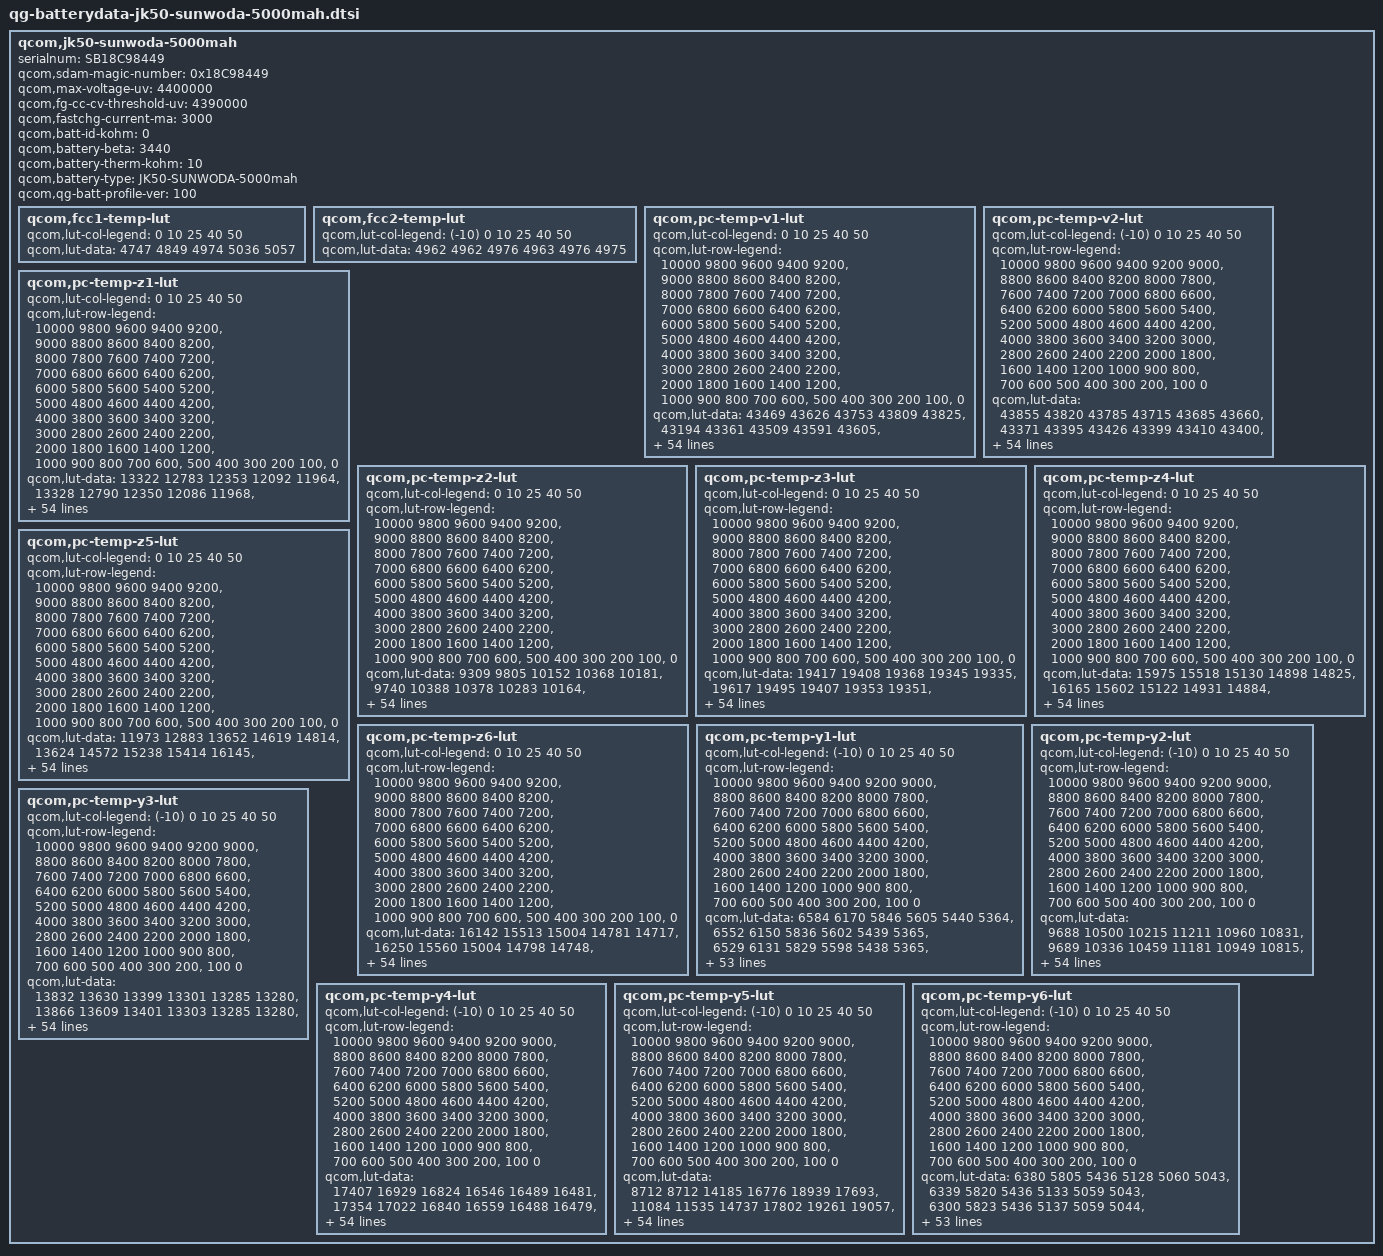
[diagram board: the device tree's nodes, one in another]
qcom,jk50-sunwoda-5000mah {
    /* 4875124_Lenovo_Ibiza_sunwoda_5000mAH_PM7250B_averaged_MasterSlave_Dec1th2020 */
    serialnum = "SB18C98449";
    qcom,sdam-magic-number = <0x18C98449>;
    qcom,max-voltage-uv = <4400000>;
    qcom,fg-cc-cv-threshold-uv = <4390000>;
    qcom,fastchg-current-ma = <3000>;
    qcom,batt-id-kohm = <0>;
    qcom,battery-beta = <3440>;
    qcom,battery-therm-kohm = <10>;
    qcom,battery-type = "JK50-SUNWODA-5000mah";
    qcom,qg-batt-profile-ver = <100>;

	qcom,fcc1-temp-lut {
		qcom,lut-col-legend = <0 10 25 40 50>;
		qcom,lut-data = <4747 4849 4974 5036 5057>;
	};

	qcom,fcc2-temp-lut {
		qcom,lut-col-legend = <(-10) 0 10 25 40 50>;
		qcom,lut-data = <4962 4962 4976 4963 4976 4975>;
	};

	qcom,pc-temp-v1-lut {
		qcom,lut-col-legend = <0 10 25 40 50>;
		qcom,lut-row-legend = <10000 9800 9600 9400 9200>,
			<9000 8800 8600 8400 8200>,
			<8000 7800 7600 7400 7200>,
			<7000 6800 6600 6400 6200>,
			<6000 5800 5600 5400 5200>,
			<5000 4800 4600 4400 4200>,
			<4000 3800 3600 3400 3200>,
			<3000 2800 2600 2400 2200>,
			<2000 1800 1600 1400 1200>,
			<1000 900 800 700 600>,
			<500 400 300 200 100>,
			<0>;
		qcom,lut-data = <43469 43626 43753 43809 43825>,
			<43194 43361 43509 43591 43605>,
			<42948 43112 43267 43360 43385>,
			<42714 42875 43026 43127 43162>,
			<42489 42643 42786 42894 42930>,
			<42273 42416 42550 42658 42692>,
			<42065 42196 42319 42425 42459>,
			<41864 41983 42092 42192 42227>,
			<41670 41778 41871 41963 41999>,
			<41485 41578 41655 41738 41772>,
			<41301 41391 41447 41516 41547>,
			<41101 41202 41256 41299 41327>,
			<40886 40997 41064 41085 41108>,
			<40655 40778 40850 40878 40897>,
			<40385 40547 40618 40674 40691>,
			<40094 40277 40392 40475 40492>,
			<39888 40016 40166 40276 40300>,
			<39766 39853 39963 40078 40115>,
			<39666 39751 39821 39902 39939>,
			<39560 39649 39716 39764 39788>,
			<39453 39522 39580 39618 39633>,
			<39344 39377 39334 39388 39412>,
			<39227 39204 39067 39089 39117>,
			<39106 38960 38892 38889 38906>,
			<38974 38745 38759 38775 38793>,
			<38820 38637 38655 38682 38702>,
			<38676 38563 38576 38588 38595>,
			<38575 38505 38510 38500 38484>,
			<38494 38457 38444 38414 38387>,
			<38435 38416 38380 38328 38306>,
			<38397 38377 38321 38251 38234>,
			<38368 38341 38265 38185 38168>,
			<38338 38305 38214 38128 38109>,
			<38311 38271 38168 38075 38050>,
			<38284 38239 38129 38028 37993>,
			<38256 38205 38090 37983 37936>,
			<38226 38173 38052 37935 37881>,
			<38187 38133 38012 37885 37827>,
			<38124 38066 37950 37818 37756>,
			<38041 37969 37856 37723 37655>,
			<37941 37862 37750 37616 37540>,
			<37811 37741 37635 37505 37427>,
			<37674 37602 37503 37380 37301>,
			<37532 37432 37335 37217 37136>,
			<37405 37291 37191 37083 37011>,
			<37300 37192 37100 36999 36934>,
			<37263 37169 37070 36969 36909>,
			<37232 37161 37050 36948 36890>,
			<37201 37147 37027 36928 36866>,
			<37145 37092 36980 36871 36800>,
			<36941 36873 36747 36614 36522>,
			<36499 36428 36311 36176 36084>,
			<35925 35856 35736 35602 35511>,
			<35155 35077 34956 34825 34730>,
			<33936 33856 33739 33613 33519>,
			<30000 30000 30000 30000 30000>;
	};

	qcom,pc-temp-v2-lut {
		qcom,lut-col-legend = <(-10) 0 10 25 40 50>;
		qcom,lut-row-legend = <10000 9800 9600 9400 9200 9000>,
			<8800 8600 8400 8200 8000 7800>,
			<7600 7400 7200 7000 6800 6600>,
			<6400 6200 6000 5800 5600 5400>,
			<5200 5000 4800 4600 4400 4200>,
			<4000 3800 3600 3400 3200 3000>,
			<2800 2600 2400 2200 2000 1800>,
			<1600 1400 1200 1000 900 800>,
			<700 600 500 400 300 200>,
			<100 0>;
		qcom,lut-data = <43855 43820 43785 43715 43685 43660>,
			<43371 43395 43426 43399 43410 43400>,
			<42943 43013 43096 43106 43146 43147>,
			<42579 42683 42800 42839 42895 42903>,
			<42268 42399 42533 42598 42656 42667>,
			<41985 42130 42283 42364 42421 42433>,
			<41666 41820 42050 42129 42188 42199>,
			<41390 41529 41826 41897 41959 41967>,
			<41327 41385 41572 41672 41732 41739>,
			<41322 41291 41267 41451 41509 41515>,
			<41315 41207 41044 41240 41288 41293>,
			<41060 41077 40963 41052 41072 41075>,
			<40528 40857 40904 40871 40859 40861>,
			<40142 40574 40746 40655 40648 40655>,
			<39815 40116 40296 40385 40435 40453>,
			<39547 39722 39902 40133 40234 40259>,
			<39374 39543 39761 39946 40051 40075>,
			<39229 39415 39661 39784 39880 39898>,
			<39044 39258 39513 39638 39718 39730>,
			<38781 39065 39290 39514 39572 39578>,
			<38555 38858 39059 39376 39411 39411>,
			<38434 38623 38859 39158 39184 39186>,
			<38345 38382 38671 38886 38925 38934>,
			<38271 38244 38500 38686 38732 38743>,
			<38209 38171 38334 38543 38589 38598>,
			<38155 38117 38197 38423 38468 38474>,
			<38103 38069 38099 38314 38359 38362>,
			<38055 38028 38018 38217 38262 38262>,
			<38007 37990 37964 38128 38173 38172>,
			<37960 37953 37927 38045 38091 38091>,
			<37912 37917 37894 37970 38018 38018>,
			<37864 37882 37863 37902 37955 37953>,
			<37815 37845 37833 37841 37898 37893>,
			<37763 37807 37800 37791 37835 37828>,
			<37712 37768 37764 37756 37764 37756>,
			<37657 37727 37725 37720 37688 37677>,
			<37596 37683 37682 37672 37607 37579>,
			<37531 37637 37635 37613 37522 37468>,
			<37459 37579 37575 37545 37442 37374>,
			<37376 37505 37497 37468 37368 37302>,
			<37291 37417 37405 37380 37290 37229>,
			<37214 37315 37295 37277 37197 37135>,
			<37141 37195 37166 37156 37088 37024>,
			<37070 37056 37038 37026 36960 36899>,
			<36997 36926 36917 36909 36851 36798>,
			<36915 36843 36812 36839 36798 36749>,
			<36867 36816 36779 36820 36787 36738>,
			<36812 36786 36747 36799 36770 36720>,
			<36742 36750 36697 36769 36740 36691>,
			<36635 36676 36616 36697 36659 36593>,
			<36418 36485 36418 36498 36388 36285>,
			<36023 36062 36003 36052 35909 35794>,
			<35447 35449 35397 35450 35288 35159>,
			<34604 34590 34552 34643 34456 34298>,
			<33231 33266 33257 33424 33243 33051>,
			<29354 28911 28617 28464 28599 28631>;
	};

	qcom,pc-temp-z1-lut {
		qcom,lut-col-legend = <0 10 25 40 50>;
		qcom,lut-row-legend = <10000 9800 9600 9400 9200>,
			<9000 8800 8600 8400 8200>,
			<8000 7800 7600 7400 7200>,
			<7000 6800 6600 6400 6200>,
			<6000 5800 5600 5400 5200>,
			<5000 4800 4600 4400 4200>,
			<4000 3800 3600 3400 3200>,
			<3000 2800 2600 2400 2200>,
			<2000 1800 1600 1400 1200>,
			<1000 900 800 700 600>,
			<500 400 300 200 100>,
			<0>;
		qcom,lut-data = <13322 12783 12353 12092 11964>,
			<13328 12790 12350 12086 11968>,
			<13352 12780 12345 12077 11961>,
			<13358 12758 12341 12069 11952>,
			<13343 12743 12334 12059 11946>,
			<13329 12730 12325 12049 11940>,
			<13324 12723 12314 12042 11936>,
			<13319 12727 12304 12035 11933>,
			<13313 12737 12303 12031 11932>,
			<13293 12740 12303 12029 11932>,
			<13270 12731 12303 12028 11932>,
			<13259 12716 12299 12029 11934>,
			<13242 12699 12294 12033 11938>,
			<13219 12677 12286 12034 11940>,
			<13186 12664 12274 12025 11937>,
			<13150 12653 12268 12016 11933>,
			<13133 12643 12267 12015 11932>,
			<13131 12642 12266 12016 11933>,
			<13130 12656 12270 12017 11934>,
			<13125 12666 12283 12020 11935>,
			<13120 12665 12290 12024 11935>,
			<13121 12663 12289 12027 11936>,
			<13126 12663 12288 12028 11937>,
			<13133 12671 12291 12030 11938>,
			<13137 12681 12301 12032 11941>,
			<13135 12687 12307 12034 11944>,
			<13131 12693 12307 12037 11946>,
			<13133 12696 12308 12039 11948>,
			<13138 12696 12309 12042 11951>,
			<13141 12697 12314 12046 11954>,
			<13143 12703 12318 12050 11958>,
			<13144 12715 12320 12053 11961>,
			<13148 12723 12325 12056 11964>,
			<13159 12723 12330 12060 11967>,
			<13172 12721 12338 12066 11971>,
			<13191 12724 12344 12072 11976>,
			<13218 12738 12349 12076 11979>,
			<13228 12750 12355 12080 11982>,
			<13215 12755 12360 12085 11986>,
			<13198 12760 12365 12089 11990>,
			<13197 12765 12369 12094 11994>,
			<13208 12780 12370 12100 11999>,
			<13219 12789 12372 12106 12005>,
			<13230 12790 12379 12109 12008>,
			<13249 12796 12399 12118 12013>,
			<13263 12810 12396 12124 12016>,
			<13267 12815 12402 12121 12014>,
			<13263 12817 12396 12123 12015>,
			<13263 12812 12396 12127 12018>,
			<13296 12815 12408 12133 12025>,
			<13294 12830 12409 12140 12030>,
			<13327 12836 12433 12150 12038>,
			<13305 12864 12427 12165 12049>,
			<13343 12895 12461 12177 12067>,
			<13343 12895 12461 12177 12067>,
			<13343 12895 12461 12177 12067>;
	};

	qcom,pc-temp-z2-lut {
		qcom,lut-col-legend = <0 10 25 40 50>;
		qcom,lut-row-legend = <10000 9800 9600 9400 9200>,
			<9000 8800 8600 8400 8200>,
			<8000 7800 7600 7400 7200>,
			<7000 6800 6600 6400 6200>,
			<6000 5800 5600 5400 5200>,
			<5000 4800 4600 4400 4200>,
			<4000 3800 3600 3400 3200>,
			<3000 2800 2600 2400 2200>,
			<2000 1800 1600 1400 1200>,
			<1000 900 800 700 600>,
			<500 400 300 200 100>,
			<0>;
		qcom,lut-data = <9309 9805 10152 10368 10181>,
			<9740 10388 10378 10283 10164>,
			<10173 10438 10515 10372 10169>,
			<10314 10457 10530 10414 10179>,
			<10315 10460 10532 10374 10220>,
			<10310 10443 10527 10317 10284>,
			<10305 10420 10490 10288 10288>,
			<10302 10404 10446 10252 10219>,
			<10297 10389 10428 10237 10155>,
			<10292 10377 10417 10242 10108>,
			<10284 10367 10407 10250 10064>,
			<10270 10358 10394 10265 10059>,
			<10239 10354 10384 10288 10076>,
			<10216 10350 10392 10295 10087>,
			<10218 10349 10421 10240 10084>,
			<10225 10363 10435 10174 10079>,
			<10225 10385 10422 10159 10084>,
			<10213 10394 10404 10154 10104>,
			<10200 10398 10400 10159 10125>,
			<10201 10404 10405 10171 10141>,
			<10214 10430 10421 10193 10161>,
			<10232 10475 10556 10322 10221>,
			<10253 10504 10712 10602 10353>,
			<10278 10522 10698 10685 10408>,
			<10306 10536 10573 10445 10325>,
			<10341 10548 10505 10215 10231>,
			<10372 10560 10507 10233 10359>,
			<10387 10565 10514 10313 10771>,
			<10397 10560 10529 10387 10933>,
			<10401 10553 10565 10488 10728>,
			<10399 10552 10591 10559 10456>,
			<10396 10555 10601 10538 10287>,
			<10396 10558 10609 10475 10146>,
			<10406 10561 10610 10409 10107>,
			<10419 10566 10607 10324 10115>,
			<10431 10573 10607 10271 10129>,
			<10444 10583 10613 10280 10161>,
			<10457 10596 10622 10305 10216>,
			<10469 10612 10639 10342 10261>,
			<10481 10629 10670 10416 10302>,
			<10493 10637 10689 10464 10327>,
			<10507 10638 10677 10456 10329>,
			<10485 10638 10662 10445 10327>,
			<10309 10640 10657 10469 10374>,
			<10552 10746 10679 10467 10374>,
			<10569 10758 10680 10438 10324>,
			<10942 10757 10669 10422 10328>,
			<11114 11385 10612 10419 10335>,
			<11107 14000 10613 10443 10353>,
			<11006 12103 10692 10515 10414>,
			<10724 14471 10668 10491 10374>,
			<10236 11170 10637 10354 10191>,
			<10094 10757 10551 10290 10139>,
			<9835 10903 10470 10257 10091>,
			<9835 10903 10470 10257 10091>,
			<9835 10903 10470 10257 10091>;
	};

	qcom,pc-temp-z3-lut {
		qcom,lut-col-legend = <0 10 25 40 50>;
		qcom,lut-row-legend = <10000 9800 9600 9400 9200>,
			<9000 8800 8600 8400 8200>,
			<8000 7800 7600 7400 7200>,
			<7000 6800 6600 6400 6200>,
			<6000 5800 5600 5400 5200>,
			<5000 4800 4600 4400 4200>,
			<4000 3800 3600 3400 3200>,
			<3000 2800 2600 2400 2200>,
			<2000 1800 1600 1400 1200>,
			<1000 900 800 700 600>,
			<500 400 300 200 100>,
			<0>;
		qcom,lut-data = <19417 19408 19368 19345 19335>,
			<19617 19495 19407 19353 19351>,
			<19668 19529 19434 19377 19363>,
			<19680 19550 19445 19392 19372>,
			<19682 19556 19453 19396 19381>,
			<19684 19556 19455 19399 19389>,
			<19681 19555 19454 19400 19392>,
			<19673 19553 19453 19401 19393>,
			<19666 19549 19451 19402 19394>,
			<19663 19546 19449 19401 19393>,
			<19660 19542 19447 19400 19391>,
			<19655 19538 19443 19400 19389>,
			<19647 19529 19439 19400 19386>,
			<19641 19516 19435 19399 19383>,
			<19646 19509 19431 19392 19380>,
			<19657 19509 19428 19384 19377>,
			<19660 19509 19426 19381 19374>,
			<19642 19506 19423 19378 19371>,
			<19616 19493 19417 19375 19368>,
			<19602 19484 19408 19369 19362>,
			<19592 19483 19404 19364 19356>,
			<19588 19483 19414 19369 19358>,
			<19588 19484 19426 19382 19365>,
			<19588 19488 19425 19386 19368>,
			<19589 19493 19415 19369 19353>,
			<19595 19493 19408 19353 19336>,
			<19602 19491 19406 19355 19350>,
			<19602 19489 19406 19363 19397>,
			<19599 19487 19407 19373 19416>,
			<19595 19485 19412 19389 19411>,
			<19589 19483 19417 19401 19403>,
			<19582 19482 19420 19400 19395>,
			<19576 19481 19422 19396 19387>,
			<19570 19479 19422 19391 19379>,
			<19564 19478 19419 19383 19372>,
			<19558 19475 19416 19375 19366>,
			<19553 19471 19411 19370 19359>,
			<19548 19466 19406 19365 19352>,
			<19544 19464 19403 19364 19349>,
			<19540 19462 19402 19362 19349>,
			<19535 19459 19400 19362 19349>,
			<19530 19455 19396 19360 19351>,
			<19505 19450 19392 19359 19354>,
			<19398 19447 19390 19360 19359>,
			<19271 19425 19383 19357 19356>,
			<19260 19419 19371 19346 19347>,
			<19259 19401 19369 19344 19340>,
			<19259 19327 19365 19339 19330>,
			<19259 19259 19362 19334 19326>,
			<19259 19259 19357 19328 19322>,
			<19259 19258 19357 19341 19335>,
			<19261 19260 19361 19355 19351>,
			<19262 19261 19364 19358 19350>,
			<19264 19260 19354 19349 19347>,
			<19264 19260 19354 19349 19347>,
			<19264 19260 19354 19349 19347>;
	};

	qcom,pc-temp-z4-lut {
		qcom,lut-col-legend = <0 10 25 40 50>;
		qcom,lut-row-legend = <10000 9800 9600 9400 9200>,
			<9000 8800 8600 8400 8200>,
			<8000 7800 7600 7400 7200>,
			<7000 6800 6600 6400 6200>,
			<6000 5800 5600 5400 5200>,
			<5000 4800 4600 4400 4200>,
			<4000 3800 3600 3400 3200>,
			<3000 2800 2600 2400 2200>,
			<2000 1800 1600 1400 1200>,
			<1000 900 800 700 600>,
			<500 400 300 200 100>,
			<0>;
		qcom,lut-data = <15975 15518 15130 14898 14825>,
			<16165 15602 15122 14931 14884>,
			<15998 15513 15104 14913 14871>,
			<15823 15323 15064 14890 14853>,
			<15649 15185 14983 14862 14834>,
			<15488 15091 14919 14832 14814>,
			<15362 15013 14876 14808 14794>,
			<15257 14951 14841 14787 14776>,
			<15172 14899 14813 14768 14760>,
			<15107 14860 14790 14750 14746>,
			<15052 14831 14770 14735 14733>,
			<14995 14807 14752 14724 14723>,
			<14933 14783 14737 14715 14715>,
			<14896 14758 14727 14710 14709>,
			<14892 14748 14720 14706 14705>,
			<14892 14754 14718 14704 14701>,
			<14888 14763 14721 14703 14698>,
			<14859 14759 14724 14702 14696>,
			<14819 14729 14716 14700 14693>,
			<14792 14707 14691 14688 14684>,
			<14768 14706 14680 14676 14676>,
			<14752 14707 14724 14703 14698>,
			<14743 14715 14787 14778 14778>,
			<14737 14782 14815 14812 14816>,
			<14737 14844 14834 14820 14817>,
			<14760 14845 14840 14823 14817>,
			<14786 14835 14829 14814 14797>,
			<14795 14824 14809 14788 14736>,
			<14800 14809 14793 14762 14705>,
			<14802 14793 14776 14736 14701>,
			<14795 14779 14762 14715 14699>,
			<14783 14766 14751 14708 14695>,
			<14772 14755 14742 14703 14692>,
			<14762 14745 14736 14701 14689>,
			<14752 14737 14733 14700 14687>,
			<14742 14730 14730 14700 14686>,
			<14732 14722 14725 14698 14686>,
			<14725 14717 14722 14696 14686>,
			<14719 14718 14722 14697 14688>,
			<14715 14720 14723 14705 14700>,
			<14712 14720 14724 14711 14710>,
			<14710 14714 14717 14704 14703>,
			<14725 14706 14707 14695 14692>,
			<14819 14700 14701 14694 14694>,
			<14884 14676 14681 14681 14685>,
			<14885 14664 14665 14663 14661>,
			<14881 14675 14658 14658 14658>,
			<14876 14743 14651 14648 14651>,
			<14869 14804 14643 14635 14633>,
			<14859 14799 14639 14630 14626>,
			<14858 14802 14653 14650 14660>,
			<14874 14816 14660 14654 14665>,
			<14883 14819 14659 14657 14673>,
			<14894 14824 14671 14666 14679>,
			<14894 14824 14671 14666 14679>,
			<14894 14824 14671 14666 14679>;
	};

	qcom,pc-temp-z5-lut {
		qcom,lut-col-legend = <0 10 25 40 50>;
		qcom,lut-row-legend = <10000 9800 9600 9400 9200>,
			<9000 8800 8600 8400 8200>,
			<8000 7800 7600 7400 7200>,
			<7000 6800 6600 6400 6200>,
			<6000 5800 5600 5400 5200>,
			<5000 4800 4600 4400 4200>,
			<4000 3800 3600 3400 3200>,
			<3000 2800 2600 2400 2200>,
			<2000 1800 1600 1400 1200>,
			<1000 900 800 700 600>,
			<500 400 300 200 100>,
			<0>;
		qcom,lut-data = <11973 12883 13652 14619 14814>,
			<13624 14572 15238 15414 16145>,
			<14390 15684 16618 17257 17212>,
			<14942 16578 17757 18592 18269>,
			<15401 17447 18732 19125 19497>,
			<15807 18258 19614 19549 20759>,
			<16226 19079 20374 20123 21727>,
			<16648 20035 21135 20900 22485>,
			<17159 21178 22080 21739 23188>,
			<17854 22466 23196 22632 23904>,
			<18631 24144 24287 23689 24646>,
			<19337 25633 25374 25323 25486>,
			<19978 26284 26421 27644 26495>,
			<20796 26624 27711 28644 27483>,
			<22643 27126 29646 27821 28446>,
			<25138 28911 30473 26811 29382>,
			<26021 30943 29277 26545 30191>,
			<25089 31303 27817 26159 31017>,
			<23908 31131 28188 26387 31718>,
			<23892 31030 30703 27769 32219>,
			<25149 34887 34466 29941 32756>,
			<27106 43230 44658 34176 33840>,
			<30572 48723 55019 40793 35621>,
			<35766 52415 52775 42253 36121>,
			<41646 54546 39376 31179 27854>,
			<50639 52727 30433 20494 18443>,
			<57834 47079 27757 19844 20763>,
			<58125 42926 26249 19945 30366>,
			<56106 40463 26392 20675 34887>,
			<53519 38875 27886 25539 35032>,
			<50020 38770 29899 30894 34828>,
			<46103 39135 33016 33657 34562>,
			<43673 39704 36626 35726 33911>,
			<41994 41396 39230 36159 33775>,
			<40861 43692 41496 35541 34316>,
			<40292 44627 42436 35001 34782>,
			<39877 45038 41879 34942 34167>,
			<39870 45345 40885 34872 32548>,
			<41202 45682 40179 34711 31417>,
			<42764 46051 39660 34112 30538>,
			<42810 45857 38857 33328 29940>,
			<41486 42490 35589 31155 29729>,
			<37802 40708 33049 28930 29780>,
			<26245 40731 33618 30892 33606>,
			<13058 40549 34936 31403 34029>,
			<11841 40760 32111 27329 29569>,
			<11763 35960 31753 26024 25067>,
			<11709 24395 30263 25468 21822>,
			<11688 11801 31095 27066 24993>,
			<11704 11837 29953 26592 27073>,
			<11753 11891 26279 27520 26082>,
			<11758 11867 23435 25863 23265>,
			<11637 11752 23368 24239 20025>,
			<11543 11618 19023 18876 16846>,
			<11543 11618 19023 18876 16846>,
			<11543 11618 19023 18876 16846>;
	};

	qcom,pc-temp-z6-lut {
		qcom,lut-col-legend = <0 10 25 40 50>;
		qcom,lut-row-legend = <10000 9800 9600 9400 9200>,
			<9000 8800 8600 8400 8200>,
			<8000 7800 7600 7400 7200>,
			<7000 6800 6600 6400 6200>,
			<6000 5800 5600 5400 5200>,
			<5000 4800 4600 4400 4200>,
			<4000 3800 3600 3400 3200>,
			<3000 2800 2600 2400 2200>,
			<2000 1800 1600 1400 1200>,
			<1000 900 800 700 600>,
			<500 400 300 200 100>,
			<0>;
		qcom,lut-data = <16142 15513 15004 14781 14717>,
			<16250 15560 15004 14798 14748>,
			<16153 15511 15004 14797 14747>,
			<16047 15407 14993 14795 14745>,
			<15931 15328 14954 14785 14741>,
			<15820 15267 14920 14769 14736>,
			<15732 15215 14896 14758 14730>,
			<15655 15172 14875 14749 14722>,
			<15592 15134 14859 14740 14715>,
			<15544 15104 14844 14732 14708>,
			<15502 15080 14832 14725 14702>,
			<15454 15058 14820 14720 14696>,
			<15397 15031 14809 14717 14692>,
			<15355 14998 14800 14713 14688>,
			<15338 14980 14790 14705 14684>,
			<15327 14976 14786 14698 14680>,
			<15312 14974 14785 14695 14676>,
			<15282 14967 14785 14694 14674>,
			<15249 14950 14779 14691 14670>,
			<15226 14939 14766 14683 14663>,
			<15207 14939 14760 14675 14657>,
			<15196 14942 14786 14690 14667>,
			<15194 14950 14821 14731 14705>,
			<15192 14982 14830 14746 14723>,
			<15194 15011 14835 14742 14717>,
			<15208 15012 14836 14736 14709>,
			<15225 15009 14831 14731 14707>,
			<15230 15005 14824 14726 14706>,
			<15233 15000 14819 14722 14705>,
			<15233 14993 14816 14720 14701>,
			<15230 14988 14813 14718 14696>,
			<15222 14983 14811 14715 14691>,
			<15217 14979 14810 14712 14686>,
			<15212 14976 14808 14708 14681>,
			<15208 14973 14806 14704 14677>,
			<15204 14971 14805 14701 14674>,
			<15200 14969 14802 14698 14670>,
			<15198 14967 14800 14695 14666>,
			<15200 14970 14800 14695 14666>,
			<15204 14976 14803 14699 14671>,
			<15208 14978 14805 14701 14675>,
			<15213 14977 14801 14699 14674>,
			<15216 14977 14798 14696 14672>,
			<15217 14980 14798 14697 14676>,
			<15205 14970 14791 14691 14670>,
			<15200 14966 14781 14678 14656>,
			<15199 14963 14777 14674 14651>,
			<15198 14956 14772 14668 14643>,
			<15197 14951 14768 14660 14633>,
			<15198 14953 14767 14656 14629>,
			<15207 14960 14778 14674 14652>,
			<15223 14974 14787 14685 14665>,
			<15239 14987 14793 14692 14671>,
			<15268 15004 14802 14696 14676>,
			<15268 15004 14802 14696 14676>,
			<15268 15004 14802 14696 14676>;
	};

	qcom,pc-temp-y1-lut {
		qcom,lut-col-legend = <(-10) 0 10 25 40 50>;
		qcom,lut-row-legend = <10000 9800 9600 9400 9200 9000>,
			<8800 8600 8400 8200 8000 7800>,
			<7600 7400 7200 7000 6800 6600>,
			<6400 6200 6000 5800 5600 5400>,
			<5200 5000 4800 4600 4400 4200>,
			<4000 3800 3600 3400 3200 3000>,
			<2800 2600 2400 2200 2000 1800>,
			<1600 1400 1200 1000 900 800>,
			<700 600 500 400 300 200>,
			<100 0>;
		qcom,lut-data = <6584 6170 5846 5605 5440 5364>,
			<6552 6150 5836 5602 5439 5365>,
			<6529 6131 5829 5598 5438 5365>,
			<6515 6116 5824 5594 5436 5365>,
			<6508 6105 5821 5590 5435 5365>,
			<6505 6101 5820 5588 5433 5364>,
			<6518 6106 5822 5585 5432 5363>,
			<6541 6113 5826 5584 5429 5360>,
			<6544 6116 5827 5584 5427 5359>,
			<6529 6115 5823 5587 5425 5359>,
			<6517 6114 5821 5590 5423 5358>,
			<6514 6116 5821 5587 5422 5356>,
			<6513 6120 5820 5583 5421 5353>,
			<6515 6121 5821 5582 5420 5353>,
			<6527 6118 5828 5586 5416 5353>,
			<6539 6118 5835 5590 5414 5353>,
			<6548 6119 5837 5591 5416 5354>,
			<6554 6121 5836 5592 5421 5354>,
			<6556 6123 5836 5594 5422 5355>,
			<6555 6126 5838 5598 5420 5355>,
			<6554 6128 5841 5602 5419 5354>,
			<6557 6127 5841 5605 5421 5355>,
			<6561 6126 5840 5608 5424 5355>,
			<6563 6126 5841 5608 5426 5356>,
			<6557 6134 5842 5607 5428 5358>,
			<6551 6142 5844 5606 5430 5360>,
			<6554 6138 5842 5607 5432 5363>,
			<6559 6129 5838 5611 5434 5366>,
			<6560 6128 5838 5615 5437 5368>,
			<6544 6137 5843 5620 5441 5371>,
			<6530 6145 5848 5625 5445 5373>,
			<6529 6142 5848 5630 5448 5376>,
			<6529 6134 5847 5635 5452 5380>,
			<6529 6132 5847 5636 5455 5383>,
			<6528 6134 5849 5636 5458 5385>,
			<6527 6136 5852 5636 5460 5388>,
			<6526 6139 5857 5640 5462 5389>,
			<6525 6143 5865 5647 5464 5391>,
			<6523 6146 5868 5651 5467 5392>,
			<6523 6150 5863 5654 5470 5395>,
			<6522 6153 5858 5655 5474 5397>,
			<6524 6150 5860 5658 5476 5399>,
			<6532 6142 5864 5661 5479 5401>,
			<6526 6144 5862 5669 5486 5405>,
			<6520 6149 5863 5674 5497 5411>,
			<6569 6152 5871 5674 5502 5413>,
			<6569 6157 5880 5675 5498 5411>,
			<6590 6168 5879 5671 5496 5411>,
			<6596 6178 5882 5676 5494 5412>,
			<6598 6157 5902 5687 5490 5411>,
			<6618 6183 5898 5686 5496 5413>,
			<6632 6204 5919 5693 5508 5419>,
			<6623 6217 5927 5704 5516 5429>,
			<6714 6228 5949 5716 5529 5440>,
			<6714 6228 5949 5716 5529 5440>,
			<6714 6228 5949 5716 5529 5440>;
	};

	qcom,pc-temp-y2-lut {
		qcom,lut-col-legend = <(-10) 0 10 25 40 50>;
		qcom,lut-row-legend = <10000 9800 9600 9400 9200 9000>,
			<8800 8600 8400 8200 8000 7800>,
			<7600 7400 7200 7000 6800 6600>,
			<6400 6200 6000 5800 5600 5400>,
			<5200 5000 4800 4600 4400 4200>,
			<4000 3800 3600 3400 3200 3000>,
			<2800 2600 2400 2200 2000 1800>,
			<1600 1400 1200 1000 900 800>,
			<700 600 500 400 300 200>,
			<100 0>;
		qcom,lut-data = <9688 10500 10215 11211 10960 10831>,
			<9689 10336 10459 11181 10949 10815>,
			<9688 10242 10635 11152 10933 10800>,
			<9686 10205 10751 11122 10913 10786>,
			<9684 10209 10818 11096 10890 10773>,
			<9681 10239 10843 11072 10866 10763>,
			<9677 10480 10793 11052 10832 10756>,
			<9672 10850 10705 11034 10800 10750>,
			<9671 10894 10695 11018 10797 10744>,
			<9672 10621 10761 11006 10821 10724>,
			<9673 10416 10811 10992 10837 10710>,
			<9673 10533 10868 10958 10811 10706>,
			<9673 10766 10958 10916 10766 10702>,
			<9672 10834 10987 10918 10760 10703>,
			<9670 10574 11058 11009 10790 10705>,
			<9669 10376 11154 11115 10832 10707>,
			<9669 10478 11309 11177 10879 10712>,
			<9668 10606 11493 11233 10941 10719>,
			<9668 10574 11537 11316 11027 10756>,
			<9668 10102 11535 11472 11169 10934>,
			<9667 9717 11531 11580 11259 11069>,
			<9667 9698 11481 11519 11213 11053>,
			<9667 9691 11348 11387 11123 11015>,
			<9666 9688 11175 11350 11093 11004>,
			<9666 9684 10871 11384 11100 11010>,
			<9665 9681 10646 11421 11112 11019>,
			<9665 9678 10623 11439 11125 11035>,
			<9665 9676 10613 11459 11148 11062>,
			<9665 9673 10592 11480 11185 11093>,
			<9664 9671 10526 11509 11261 11132>,
			<9664 9670 10462 11529 11326 11171>,
			<9664 9668 10434 11512 11368 11222>,
			<9663 9667 10399 11465 11416 11288>,
			<9663 9666 10320 11433 11427 11308>,
			<9663 9665 10070 11419 11398 11294>,
			<9663 9664 9852 11405 11357 11270>,
			<9663 9663 9770 11374 11317 11222>,
			<9663 9663 9716 11323 11274 11151>,
			<9663 9662 9694 11271 11246 11129>,
			<9662 9662 9682 11223 11224 11136>,
			<9662 9661 9675 11171 11212 11143>,
			<9662 9661 9671 11104 11233 11136>,
			<9662 9661 9668 11024 11265 11103>,
			<9662 9661 9666 10945 11145 11029>,
			<9661 9661 9664 10864 11025 10920>,
			<9661 9660 9664 10820 11018 10849>,
			<9661 9660 9663 10853 11055 10878>,
			<9661 9660 9662 10832 11082 10897>,
			<9660 9660 9662 10838 11110 10946>,
			<9660 9660 9662 10868 11145 10978>,
			<9660 9659 9661 10849 11102 10857>,
			<9659 9659 9661 10718 10969 10762>,
			<9658 9659 9659 10538 10858 10650>,
			<9655 9658 9658 10185 10793 10560>,
			<9655 9658 9658 10185 10793 10560>,
			<9655 9658 9658 10185 10793 10560>;
	};

	qcom,pc-temp-y3-lut {
		qcom,lut-col-legend = <(-10) 0 10 25 40 50>;
		qcom,lut-row-legend = <10000 9800 9600 9400 9200 9000>,
			<8800 8600 8400 8200 8000 7800>,
			<7600 7400 7200 7000 6800 6600>,
			<6400 6200 6000 5800 5600 5400>,
			<5200 5000 4800 4600 4400 4200>,
			<4000 3800 3600 3400 3200 3000>,
			<2800 2600 2400 2200 2000 1800>,
			<1600 1400 1200 1000 900 800>,
			<700 600 500 400 300 200>,
			<100 0>;
		qcom,lut-data = <13832 13630 13399 13301 13285 13280>,
			<13866 13609 13401 13303 13285 13280>,
			<13870 13595 13402 13305 13285 13281>,
			<13850 13585 13404 13307 13286 13282>,
			<13812 13578 13405 13308 13286 13283>,
			<13764 13571 13407 13309 13287 13284>,
			<13679 13556 13410 13310 13287 13284>,
			<13585 13535 13414 13310 13288 13285>,
			<13567 13511 13411 13311 13289 13285>,
			<13577 13446 13386 13313 13290 13286>,
			<13585 13401 13367 13314 13291 13286>,
			<13593 13416 13365 13317 13291 13287>,
			<13606 13444 13363 13319 13292 13287>,
			<13604 13448 13363 13319 13292 13287>,
			<13569 13424 13360 13318 13292 13288>,
			<13541 13401 13358 13315 13292 13289>,
			<13548 13393 13357 13312 13293 13289>,
			<13564 13388 13355 13308 13296 13290>,
			<13567 13386 13352 13307 13296 13290>,
			<13557 13387 13343 13308 13295 13290>,
			<13548 13388 13332 13308 13293 13290>,
			<13552 13375 13324 13305 13289 13288>,
			<13567 13352 13316 13298 13284 13282>,
			<13584 13347 13307 13294 13282 13280>,
			<13606 13357 13293 13293 13281 13279>,
			<13631 13372 13283 13293 13281 13279>,
			<13652 13389 13288 13291 13281 13279>,
			<13674 13410 13301 13290 13280 13278>,
			<13698 13433 13305 13289 13280 13278>,
			<13726 13457 13306 13288 13280 13278>,
			<13756 13484 13307 13288 13279 13278>,
			<13785 13512 13309 13287 13279 13278>,
			<13814 13542 13314 13286 13280 13278>,
			<13843 13575 13320 13286 13280 13278>,
			<13873 13612 13330 13288 13280 13278>,
			<13904 13651 13344 13290 13280 13279>,
			<13937 13693 13362 13292 13280 13279>,
			<13973 13737 13388 13293 13279 13278>,
			<14007 13777 13415 13295 13279 13278>,
			<14036 13814 13444 13297 13280 13280>,
			<14065 13849 13476 13299 13282 13282>,
			<14097 13882 13513 13301 13283 13282>,
			<14132 13912 13555 13303 13284 13281>,
			<14178 13940 13606 13305 13284 13280>,
			<14235 13971 13661 13308 13284 13281>,
			<14274 13998 13660 13312 13288 13286>,
			<14270 13994 13662 13312 13291 13288>,
			<14318 14038 13710 13318 13293 13289>,
			<14368 14080 13751 13326 13295 13291>,
			<14442 14122 13785 13332 13295 13289>,
			<14501 14160 13802 13334 13291 13286>,
			<14585 14201 13840 13333 13292 13287>,
			<14860 14279 13949 13342 13297 13292>,
			<15472 14430 14075 13362 13307 13303>,
			<15472 14430 14075 13362 13307 13303>,
			<15472 14430 14075 13362 13307 13303>;
	};

	qcom,pc-temp-y4-lut {
		qcom,lut-col-legend = <(-10) 0 10 25 40 50>;
		qcom,lut-row-legend = <10000 9800 9600 9400 9200 9000>,
			<8800 8600 8400 8200 8000 7800>,
			<7600 7400 7200 7000 6800 6600>,
			<6400 6200 6000 5800 5600 5400>,
			<5200 5000 4800 4600 4400 4200>,
			<4000 3800 3600 3400 3200 3000>,
			<2800 2600 2400 2200 2000 1800>,
			<1600 1400 1200 1000 900 800>,
			<700 600 500 400 300 200>,
			<100 0>;
		qcom,lut-data = <17407 16929 16824 16546 16489 16481>,
			<17354 17022 16840 16559 16488 16479>,
			<17332 17085 16866 16570 16487 16477>,
			<17334 17125 16894 16579 16485 16475>,
			<17353 17147 16917 16586 16484 16474>,
			<17382 17158 16927 16588 16484 16472>,
			<17446 17142 16928 16586 16483 16471>,
			<17550 17113 16927 16581 16483 16470>,
			<17661 17160 16927 16581 16483 16470>,
			<17805 17441 16936 16582 16484 16471>,
			<17888 17645 16963 16584 16486 16471>,
			<17705 17595 17090 16592 16487 16473>,
			<17341 17474 17267 16606 16490 16475>,
			<17157 17347 17266 16609 16493 16478>,
			<17042 17116 17009 16602 16498 16482>,
			<16964 16957 16820 16597 16506 16487>,
			<16928 16956 16853 16611 16517 16493>,
			<16892 16968 16916 16642 16533 16502>,
			<16840 16960 16924 16672 16554 16517>,
			<16741 16898 16865 16705 16588 16549>,
			<16669 16815 16793 16726 16608 16570>,
			<16663 16722 16738 16679 16576 16547>,
			<16661 16622 16687 16575 16510 16499>,
			<16661 16595 16645 16528 16483 16477>,
			<16662 16596 16608 16514 16473 16467>,
			<16663 16597 16576 16507 16468 16463>,
			<16667 16598 16543 16506 16469 16464>,
			<16673 16602 16512 16505 16472 16465>,
			<16679 16606 16507 16504 16475 16468>,
			<16683 16613 16522 16500 16481 16474>,
			<16689 16622 16543 16495 16488 16482>,
			<16695 16632 16561 16492 16498 16493>,
			<16704 16643 16579 16488 16508 16507>,
			<16712 16655 16598 16487 16510 16511>,
			<16723 16666 16620 16496 16504 16512>,
			<16732 16677 16640 16507 16496 16513>,
			<16734 16686 16657 16513 16486 16501>,
			<16733 16694 16673 16517 16473 16476>,
			<16731 16699 16683 16523 16471 16469>,
			<16727 16701 16690 16532 16478 16479>,
			<16724 16702 16694 16543 16487 16490>,
			<16727 16699 16694 16556 16492 16493>,
			<16740 16687 16692 16570 16496 16494>,
			<16760 16671 16693 16581 16487 16475>,
			<16789 16661 16699 16592 16482 16465>,
			<16801 16663 16697 16600 16495 16493>,
			<16776 16661 16701 16592 16513 16522>,
			<16798 16684 16730 16619 16544 16557>,
			<16822 16717 16771 16656 16580 16590>,
			<16834 16751 16828 16693 16593 16586>,
			<16829 16756 16854 16698 16540 16515>,
			<16821 16733 16831 16663 16514 16493>,
			<16872 16727 16816 16674 16524 16494>,
			<17103 16752 16815 16714 16550 16506>,
			<17103 16752 16815 16714 16550 16506>,
			<17103 16752 16815 16714 16550 16506>;
	};

	qcom,pc-temp-y5-lut {
		qcom,lut-col-legend = <(-10) 0 10 25 40 50>;
		qcom,lut-row-legend = <10000 9800 9600 9400 9200 9000>,
			<8800 8600 8400 8200 8000 7800>,
			<7600 7400 7200 7000 6800 6600>,
			<6400 6200 6000 5800 5600 5400>,
			<5200 5000 4800 4600 4400 4200>,
			<4000 3800 3600 3400 3200 3000>,
			<2800 2600 2400 2200 2000 1800>,
			<1600 1400 1200 1000 900 800>,
			<700 600 500 400 300 200>,
			<100 0>;
		qcom,lut-data = <8712 8712 14185 16776 18939 17693>,
			<11084 11535 14737 17802 19261 19057>,
			<12553 13614 15507 18572 19365 19976>,
			<13330 14958 16371 19101 19336 20534>,
			<13637 15750 17205 19410 19253 20816>,
			<13690 16173 17883 19513 19199 20908>,
			<13073 16787 18598 19285 19112 20534>,
			<12037 17490 19267 18892 18953 19910>,
			<12231 17303 18842 18772 18832 19734>,
			<15208 15614 15494 18792 18655 19483>,
			<18117 15112 13119 18769 18421 19146>,
			<20120 19044 14660 17710 17937 18523>,
			<22145 24656 17573 15917 17258 17712>,
			<22037 25337 18731 15642 16797 17361>,
			<18765 20169 18622 16905 16428 17224>,
			<16279 16064 18427 17902 16138 17068>,
			<18072 16933 19265 17220 15838 16485>,
			<21652 19117 20807 15846 15543 15677>,
			<22218 20842 21759 15764 15565 15478>,
			<18237 22532 22567 18476 16070 15665>,
			<14507 23565 23114 21229 16843 16014>,
			<13691 20976 23326 22224 18298 17697>,
			<13203 15329 23478 22879 20127 20376>,
			<13082 13339 23336 23392 20745 21084>,
			<13163 13137 21107 23897 20842 20980>,
			<13278 13051 19101 24191 20767 20763>,
			<13365 13152 18685 24058 20339 20021>,
			<13489 13418 18114 23755 19638 18758>,
			<13641 13633 17744 23726 19202 18088>,
			<13879 13857 17224 24484 18791 17722>,
			<14093 14082 16750 25184 18532 17543>,
			<14230 14267 16509 24482 19232 17674>,
			<14392 14473 16301 22649 20956 18116>,
			<14483 14710 16057 21974 22170 18922>,
			<14612 14995 15706 22244 23337 21342>,
			<14719 15348 15540 22519 24044 23268>,
			<14774 15935 15749 22168 23536 23009>,
			<14914 16721 16119 21002 22373 22263>,
			<14921 16984 16255 19925 21711 22061>,
			<14553 16814 16214 19031 21346 22677>,
			<14099 16608 16144 18215 21154 23249>,
			<13868 16536 15962 17521 21491 23318>,
			<13715 16442 15642 16945 21998 23112>,
			<13693 15629 15535 16571 20426 21598>,
			<13761 14688 15356 16321 18410 18927>,
			<14000 14306 14798 16456 17655 16710>,
			<14304 14527 15023 16756 17563 16166>,
			<14443 14410 15296 16593 17059 15405>,
			<14734 14570 15551 16798 16713 15340>,
			<15463 14864 16344 17218 16517 15109>,
			<15612 15527 16468 17534 17340 15739>,
			<14472 14950 15787 17332 18272 16346>,
			<13321 14510 14988 16739 18193 16735>,
			<11889 14027 14398 16378 21078 22912>,
			<11889 14027 14398 16378 21078 22912>,
			<11889 14027 14398 16378 21078 22912>;
	};

	qcom,pc-temp-y6-lut {
		qcom,lut-col-legend = <(-10) 0 10 25 40 50>;
		qcom,lut-row-legend = <10000 9800 9600 9400 9200 9000>,
			<8800 8600 8400 8200 8000 7800>,
			<7600 7400 7200 7000 6800 6600>,
			<6400 6200 6000 5800 5600 5400>,
			<5200 5000 4800 4600 4400 4200>,
			<4000 3800 3600 3400 3200 3000>,
			<2800 2600 2400 2200 2000 1800>,
			<1600 1400 1200 1000 900 800>,
			<700 600 500 400 300 200>,
			<100 0>;
		qcom,lut-data = <6380 5805 5436 5128 5060 5043>,
			<6339 5820 5436 5133 5059 5043>,
			<6300 5823 5436 5137 5059 5044>,
			<6263 5817 5435 5139 5059 5044>,
			<6228 5808 5435 5141 5058 5045>,
			<6196 5797 5434 5141 5058 5045>,
			<6161 5779 5432 5140 5058 5045>,
			<6131 5756 5429 5138 5059 5045>,
			<6132 5754 5423 5137 5059 5045>,
			<6176 5786 5405 5138 5060 5045>,
			<6209 5810 5393 5139 5060 5046>,
			<6164 5809 5423 5142 5061 5047>,
			<6071 5801 5474 5146 5062 5047>,
			<6016 5773 5474 5147 5063 5048>,
			<5965 5687 5403 5143 5064 5050>,
			<5933 5626 5350 5140 5066 5052>,
			<5930 5627 5358 5143 5070 5054>,
			<5928 5631 5375 5150 5077 5057>,
			<5920 5631 5376 5157 5084 5061>,
			<5890 5617 5356 5167 5091 5070>,
			<5866 5597 5331 5173 5096 5076>,
			<5870 5572 5313 5158 5084 5067>,
			<5883 5545 5297 5123 5061 5049>,
			<5897 5539 5283 5109 5052 5041>,
			<5915 5556 5270 5105 5049 5038>,
			<5934 5580 5261 5103 5047 5037>,
			<5953 5601 5261 5103 5048 5037>,
			<5971 5625 5267 5104 5049 5037>,
			<5991 5649 5277 5104 5050 5038>,
			<6013 5676 5294 5104 5052 5040>,
			<6036 5703 5314 5104 5054 5043>,
			<6059 5733 5336 5104 5057 5046>,
			<6084 5763 5360 5104 5061 5050>,
			<6109 5796 5387 5106 5062 5052>,
			<6135 5830 5416 5112 5061 5053>,
			<6162 5866 5448 5120 5059 5053>,
			<6189 5903 5483 5126 5056 5050>,
			<6216 5940 5522 5132 5053 5042>,
			<6242 5974 5562 5139 5052 5040>,
			<6265 6005 5603 5148 5055 5045>,
			<6288 6033 5647 5159 5060 5050>,
			<6317 6058 5690 5172 5063 5051>,
			<6351 6081 5735 5188 5065 5051>,
			<6394 6101 5786 5207 5064 5046>,
			<6448 6126 5839 5229 5064 5044>,
			<6488 6149 5840 5244 5073 5057>,
			<6483 6146 5843 5234 5079 5066>,
			<6531 6187 5891 5254 5089 5077>,
			<6577 6230 5935 5276 5100 5088>,
			<6642 6272 5983 5293 5103 5085>,
			<6694 6308 6006 5299 5086 5063>,
			<6767 6337 6035 5296 5081 5059>,
			<7031 6402 6121 5344 5090 5064>,
			<7621 6537 6227 5402 5107 5076>,
			<7621 6537 6227 5402 5107 5076>,
			<7621 6537 6227 5402 5107 5076>;
	};

};
